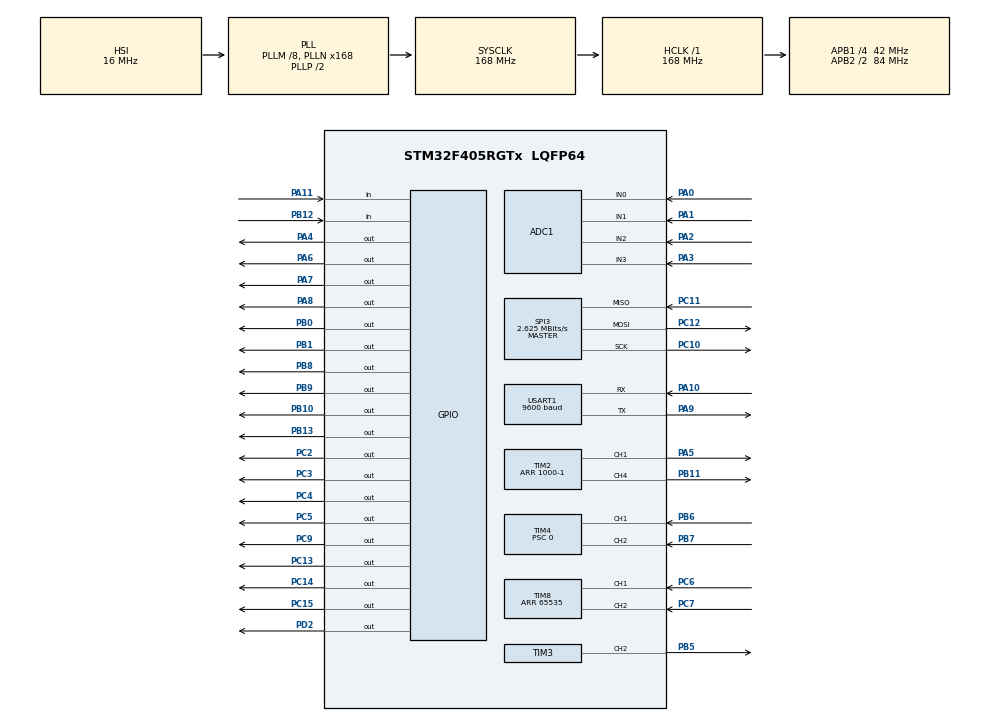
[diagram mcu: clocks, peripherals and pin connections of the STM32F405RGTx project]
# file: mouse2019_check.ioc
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ADC1.Channel-13\#ChannelRegularConversion=ADC_CHANNEL_0
ADC1.ClockPrescaler=ADC_CLOCK_SYNC_PCLK_DIV4
ADC1.ContinuousConvMode=DISABLE
ADC1.DMAContinuousRequests=DISABLE
ADC1.DiscontinuousConvMode=DISABLE
ADC1.NbrOfConversion=1
ADC1.NbrOfConversionFlag=1
ADC1.Rank-13\#ChannelRegularConversion=1
ADC1.SamplingTime-13\#ChannelRegularConversion=ADC_SAMPLETIME_3CYCLES
ADC1.master=1
Mcu.Family=STM32F4
Mcu.Name=STM32F405RGTx
Mcu.Package=LQFP64
NVIC.PriorityGroup=NVIC_PRIORITYGROUP_4
NVIC.TIM3_IRQn=true\:0\:0\:false\:false\:true\:true\:false
NVIC.TIM4_IRQn=true\:0\:0\:false\:false\:true\:true\:false
NVIC.TIM6_DAC_IRQn=true\:0\:0\:false\:false\:true\:true\:true
PA0-WKUP.Signal=ADCx_IN0
PA1.Signal=ADCx_IN1
PA10.Mode=Asynchronous
PA10.Signal=USART1_RX
PA11.GPIO_Mode=GPIO_MODE_INPUT
PA11.GPIO_PuPd=GPIO_NOPULL
PA11.Signal=GPIO_Input
PA2.Signal=ADCx_IN2
PA3.Signal=ADCx_IN3
PA4.GPIO_ModeDefaultOutputPP=GPIO_MODE_OUTPUT_PP
PA4.GPIO_PuPd=GPIO_NOPULL
PA4.GPIO_Speed=GPIO_SPEED_FREQ_LOW
PA4.PinState=GPIO_PIN_RESET
PA4.Signal=GPIO_Output
PA5.Signal=S_TIM2_CH1_ETR
PA6.GPIO_ModeDefaultOutputPP=GPIO_MODE_OUTPUT_PP
PA6.GPIO_PuPd=GPIO_NOPULL
PA6.GPIO_Speed=GPIO_SPEED_FREQ_LOW
PA6.PinState=GPIO_PIN_RESET
PA6.Signal=GPIO_Output
PA7.PinState=GPIO_PIN_RESET
PA7.Signal=GPIO_Output
PA8.PinState=GPIO_PIN_RESET
PA8.Signal=GPIO_Output
PA9.Mode=Asynchronous
PA9.Signal=USART1_TX
PB0.PinState=GPIO_PIN_RESET
PB0.Signal=GPIO_Output
PB1.PinState=GPIO_PIN_RESET
PB1.Signal=GPIO_Output
PB10.PinState=GPIO_PIN_RESET
PB10.Signal=GPIO_Output
PB11.Signal=S_TIM2_CH4
PB12.GPIO_PuPd=GPIO_PULLUP
PB12.Signal=GPIO_Input
PB13.PinState=GPIO_PIN_RESET
PB13.Signal=GPIO_Output
PB5.Signal=S_TIM3_CH2
PB6.Signal=S_TIM4_CH1
PB7.Signal=S_TIM4_CH2
PB8.GPIO_ModeDefaultOutputPP=GPIO_MODE_OUTPUT_PP
PB8.GPIO_PuPd=GPIO_NOPULL
PB8.GPIO_Speed=GPIO_SPEED_FREQ_LOW
PB8.PinState=GPIO_PIN_RESET
PB8.Signal=GPIO_Output
PB9.PinState=GPIO_PIN_RESET
PB9.Signal=GPIO_Output
PC10.Mode=Full_Duplex_Master
PC10.Signal=SPI3_SCK
PC11.Mode=Full_Duplex_Master
PC11.Signal=SPI3_MISO
PC12.Mode=Full_Duplex_Master
PC12.Signal=SPI3_MOSI
PC13-ANTI_TAMP.GPIO_ModeDefaultOutputPP=GPIO_MODE_OUTPUT_PP
PC13-ANTI_TAMP.GPIO_PuPd=GPIO_NOPULL
PC13-ANTI_TAMP.GPIO_Speed=GPIO_SPEED_FREQ_LOW
PC13-ANTI_TAMP.PinState=GPIO_PIN_RESET
PC13-ANTI_TAMP.Signal=GPIO_Output
PC14-OSC32_IN.PinState=GPIO_PIN_RESET
PC14-OSC32_IN.Signal=GPIO_Output
PC15-OSC32_OUT.PinState=GPIO_PIN_RESET
PC15-OSC32_OUT.Signal=GPIO_Output
PC2.GPIO_ModeDefaultOutputPP=GPIO_MODE_OUTPUT_PP
PC2.GPIO_PuPd=GPIO_NOPULL
PC2.GPIO_Speed=GPIO_SPEED_FREQ_LOW
PC2.PinState=GPIO_PIN_RESET
PC2.Signal=GPIO_Output
PC3.GPIO_ModeDefaultOutputPP=GPIO_MODE_OUTPUT_PP
PC3.GPIO_PuPd=GPIO_NOPULL
PC3.GPIO_Speed=GPIO_SPEED_FREQ_LOW
PC3.PinState=GPIO_PIN_RESET
PC3.Signal=GPIO_Output
PC4.PinState=GPIO_PIN_RESET
PC4.Signal=GPIO_Output
PC5.PinState=GPIO_PIN_RESET
PC5.Signal=GPIO_Output
PC6.Signal=S_TIM8_CH1
PC7.Signal=S_TIM8_CH2
PC9.PinState=GPIO_PIN_RESET
PC9.Signal=GPIO_Output
PD2.PinState=GPIO_PIN_RESET
PD2.Signal=GPIO_Output
ProjectManager.HeapSize=0x200
ProjectManager.StackSize=0x400
ProjectManager.TargetToolchain=STM32CubeIDE
RCC.48MHZClocksFreq_Value=84000000
RCC.AHBFreq_Value=168000000
RCC.APB1CLKDivider=RCC_HCLK_DIV4
RCC.APB1Freq_Value=42000000
RCC.APB1TimFreq_Value=84000000
RCC.APB2CLKDivider=RCC_HCLK_DIV2
RCC.APB2Freq_Value=84000000
RCC.APB2TimFreq_Value=168000000
RCC.CortexFreq_Value=168000000
RCC.HCLKFreq_Value=168000000
RCC.HSE_VALUE=25000000
RCC.HSI_VALUE=16000000
RCC.LSE_VALUE=32768
RCC.PLLM=8
RCC.PLLN=168
RCC.SYSCLKFreq_VALUE=168000000
RCC.SYSCLKSource=RCC_SYSCLKSOURCE_PLLCLK
RCC.VCOOutputFreq_Value=336000000
SH.ADCx_IN0.0=ADC1_IN0,IN0
SH.ADCx_IN1.0=ADC1_IN1,IN1
SH.ADCx_IN2.0=ADC1_IN2,IN2
SH.ADCx_IN3.0=ADC1_IN3,IN3
SH.S_TIM2_CH1_ETR.0=TIM2_CH1,PWM Generation1 CH1
SH.S_TIM2_CH4.0=TIM2_CH4,PWM Generation4 CH4
SH.S_TIM3_CH2.0=TIM3_CH2,PWM Generation2 CH2
SH.S_TIM4_CH1.0=TIM4_CH1,Encoder_Interface
SH.S_TIM4_CH2.0=TIM4_CH2,Encoder_Interface
SH.S_TIM8_CH1.0=TIM8_CH1,Encoder_Interface
SH.S_TIM8_CH2.0=TIM8_CH2,Encoder_Interface
SPI3.BaudRatePrescaler=SPI_BAUDRATEPRESCALER_16
SPI3.CalculateBaudRate=2.625 MBits/s
SPI3.Direction=SPI_DIRECTION_2LINES
SPI3.Mode=SPI_MODE_MASTER
SPI3.VirtualType=VM_MASTER
TIM2.Channel-PWM\ Generation1\ CH1=TIM_CHANNEL_1
TIM2.Channel-PWM\ Generation4\ CH4=TIM_CHANNEL_4
TIM2.Period=1000-1
TIM3.Channel-PWM\ Generation2\ CH2=TIM_CHANNEL_2
TIM3.Period=0
TIM3.Prescaler=84-1
TIM4.EncoderMode=TIM_ENCODERMODE_TI12
TIM4.Period=65535
TIM4.Prescaler=0
TIM6.Period=1000-1
TIM6.Prescaler=84-1
TIM8.CounterMode=TIM_COUNTERMODE_UP
TIM8.EncoderMode=TIM_ENCODERMODE_TI12
TIM8.Period=65535
USART1.BaudRate=9600
USART1.VirtualMode=VM_ASYNC
VP_TIM2_VS_ClockSourceINT.Mode=Internal
VP_TIM3_VS_ClockSourceINT.Mode=Internal
VP_TIM6_VS_ClockSourceINT.Mode=Enable_Timer
board=custom

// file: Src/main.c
/* USER CODE BEGIN Header */
/**
  ******************************************************************************
  * @file           : main.c
  * @brief          : Main program body
  ******************************************************************************
  * @attention
  *
  * <h2><center>&copy; Copyright (c) 2019 STMicroelectronics.
  * All rights reserved.</center></h2>
  *
  * This software component is licensed by ST under BSD 3-Clause license,
  * the "License"; You may not use this file except in compliance with the
  * License. You may obtain a copy of the License at:
  *                        opensource.org/licenses/BSD-3-Clause
  *
  ******************************************************************************
  */
/* USER CODE END Header */

#include "main.h"

/* USER CODE BEGIN Includes */
#include <stdio.h>
//#include <string.h>
#include "math.h"

#define MAIN_C_
#include "global.h"

/* USER CODE END Includes */

/* USER CODE BEGIN PD */

#define DIAMETER 24.2//22.5//23.4
#define TREAD 66
#define sensor_wait 3000
#define log_allay 200

//gyro
#define WHO_AM_I 0x75
#define PWR_MGMT_1 0x6B
#define CONFIG 0x1A
#define GYRO_CONFIG 0x1B
#define GYRO_ZOUT_H 0x47
#define GYRO_ZOUT_L 0x48
#define GYRO_FACTOR 16.4

/* USER CODE END PD */

ADC_HandleTypeDef hadc1;

SPI_HandleTypeDef hspi3;

TIM_HandleTypeDef htim2;
TIM_HandleTypeDef htim3;
TIM_HandleTypeDef htim4;
TIM_HandleTypeDef htim6;
TIM_HandleTypeDef htim8;

UART_HandleTypeDef huart1;

/* USER CODE BEGIN PV */

float cnt_r = 0;
float dist_r = 0;
float speed_r = 0;
float cnt_l = 0;
float dist_l = 0;
float speed_l = 0;
float speed_G = 0;

int mode = 0;
int cnt = 0;
int get_cnt = 0;

float speed_min_l = 0;
float speed_max_l = 0;
float speed_min_r = 0;
float speed_max_r = 0;
float pulse_l, pulse_r;

float accel_l = 0;
float accel_r = 0;
float target_speed_l = 0;
float target_speed_r = 0;
float target_dist = 0;

float degree_z = 0;
float target_degree_z = 0;
float target_omega_z = 0;
float target_degaccel_z = 0;
float omega_min = 0;
float omega_max = 0;

int get_speed_l[log_allay];
int get_speed_r[log_allay];

int value1, value2, value3, value4;

float epsilon_sum = 0; 	//dif sum
float old_epsilon = 0; 	//
float epsilon_dif = 0;	//dif of dif
float epsilon_l = 0; 	//dif between target & current
float epsilon_r = 0;	//dif between target & current
float Kp = 4;
float Ti = 1000;
float Td = 0;

//#define NUMBER_OF_VRS 4
//static uint16_t vr_values[NUMBER_OF_VRS];

//#define ADC_CONVERTED_DATA_BUFFER_SIZE ((uint32_t) 4)

/* USER CODE END PV */

void SystemClock_Config(void);
static void MX_GPIO_Init(void);
static void MX_USART1_UART_Init(void);
static void MX_ADC1_Init(void);
static void MX_TIM4_Init(void);
static void MX_TIM8_Init(void);
static void MX_TIM2_Init(void);
static void MX_TIM6_Init(void);
static void MX_TIM3_Init(void);
static void MX_SPI3_Init(void);
/* USER CODE BEGIN PFP */
void buzzer(int, int);
int get_adc_value(ADC_HandleTypeDef*, uint32_t);
void gyro_init(void);
uint8_t read_byte(uint8_t reg);
void write_byte(uint8_t reg, uint8_t val);
float gyro_read_z(void);
void drive_dir(uint8_t, uint8_t);

/* USER CODE END PFP */

/* USER CODE BEGIN 0 */
int __io_putchar(int c){
  if(c == '\n'){
    int _c = '\r';
    HAL_UART_Transmit(&huart1, &_c, 1, 1);
  }
  HAL_UART_Transmit(&huart1, &c, 1, 1);
  return 0;
}

void HAL_TIM_PeriodElapsedCallback(TIM_HandleTypeDef *htim){
	TIM_OC_InitTypeDef ConfigOC;
	ConfigOC.OCMode = TIM_OCMODE_PWM1;
	ConfigOC.OCPolarity = TIM_OCPOLARITY_HIGH;
	ConfigOC.OCFastMode = TIM_OCFAST_DISABLE;

	if(htim == &htim6){
/*	  ledOn ++;
	  ledOn = ledOn % 2;
	  switch(ledOn){
	  case 0:
		  HAL_GPIO_WritePin(GPIOC, GPIO_PIN_2, GPIO_PIN_SET);   //
		  break;

	  case 1:
		  HAL_GPIO_WritePin(GPIOC, GPIO_PIN_2, GPIO_PIN_RESET);   //
		  break;
	  }
*/

		cnt_l = TIM4 -> CNT;
		cnt_r = TIM8 -> CNT;
		if(cnt_l > 40000) cnt_l = cnt_l - 65535;
		if(cnt_r > 40000) cnt_r = cnt_r - 65535;
		cnt_r = cnt_r * -1;

		dist_l = dist_l + cnt_l * (DIAMETER * M_PI * 11 / 40 / 4096 / 4);
		dist_r = dist_r + cnt_r * (DIAMETER * M_PI * 11 / 40 / 4096 / 4);

		speed_l = cnt_l * (DIAMETER * M_PI * 11 / 40 / 4096 / 4) / 0.001;
		speed_r = cnt_r * (DIAMETER * M_PI * 11 / 40 / 4096 / 4) / 0.001;

		TIM4 -> CNT = 0;
		TIM8 -> CNT = 0;

		if(MF.FLAG.DRV){
			target_speed_l += accel_l * 0.001;
			target_speed_l = max(min(target_speed_l, speed_max_l), speed_min_l);
			epsilon_l = target_speed_l - speed_l;
			pulse_l = Kp * epsilon_l;
			if(pulse_l > 0){
				drive_dir(0, 0);
				ConfigOC.Pulse = pulse_l;
				HAL_TIM_PWM_ConfigChannel(&htim2, &ConfigOC, TIM_CHANNEL_1);
				HAL_TIM_PWM_Start(&htim2,TIM_CHANNEL_1);
			}
			else if(pulse_l < 0){
				drive_dir(0, 1);
				ConfigOC.Pulse = -pulse_l;
				HAL_TIM_PWM_ConfigChannel(&htim2, &ConfigOC, TIM_CHANNEL_1);
				HAL_TIM_PWM_Start(&htim2,TIM_CHANNEL_1);
			}

			target_speed_r += accel_r * 0.001;
			target_speed_r = max(min(target_speed_r, speed_max_r), speed_min_r);
			epsilon_r = target_speed_r - speed_r;
			pulse_r = Kp * epsilon_r;
			if(pulse_r > 0){
				drive_dir(1, 0);
				ConfigOC.Pulse = pulse_r;
				HAL_TIM_PWM_ConfigChannel(&htim2, &ConfigOC, TIM_CHANNEL_4);
				HAL_TIM_PWM_Start(&htim2,TIM_CHANNEL_4);
			}
			else if(pulse_r < 0){
				drive_dir(1, 1);
				ConfigOC.Pulse = -pulse_r;
				HAL_TIM_PWM_ConfigChannel(&htim2, &ConfigOC, TIM_CHANNEL_4);
				HAL_TIM_PWM_Start(&htim2,TIM_CHANNEL_4);
			}
			if(cnt >= 5 && MF.FLAG.LOG){
				cnt = 0;
				if(get_cnt < log_allay){
					get_speed_l[get_cnt] = speed_l;
					get_speed_r[get_cnt] = speed_r;
					get_cnt++;
				}
			}
		}else{
			drive_dir(0, 2);
			drive_dir(1, 2);
		}

		//gyro interrupt
		degree_z += gyro_read_z() * 0.001;

		if(MF.FLAG.ENKAI){
			target_dist = TREAD*M_PI/360*(degree_z-target_degree_z);
			if(target_dist > 0){
				target_speed_l = sqrt(2*accel_l*target_dist);
				target_speed_r = -1 * target_speed_l;
			}else{
				target_speed_l = sqrt(2*accel_l*target_dist*-1)*-1;
				target_speed_r = -1 * target_speed_l;
			}

			epsilon_l = target_speed_l - speed_l;
			pulse_l = Kp * epsilon_l;
			if(pulse_l > 0){
				drive_dir(0, 0);
				ConfigOC.Pulse = pulse_l;
				HAL_TIM_PWM_ConfigChannel(&htim2, &ConfigOC, TIM_CHANNEL_1);
				HAL_TIM_PWM_Start(&htim2,TIM_CHANNEL_1);
			}
			else if(pulse_l < 0){
				drive_dir(0, 1);
				ConfigOC.Pulse = -pulse_l;
				HAL_TIM_PWM_ConfigChannel(&htim2, &ConfigOC, TIM_CHANNEL_1);
				HAL_TIM_PWM_Start(&htim2,TIM_CHANNEL_1);
			}

			epsilon_r = target_speed_r - speed_r;
			pulse_r = Kp * epsilon_r;
			if(pulse_r > 0){
				drive_dir(1, 0);
				ConfigOC.Pulse = pulse_r;
				HAL_TIM_PWM_ConfigChannel(&htim2, &ConfigOC, TIM_CHANNEL_4);
				HAL_TIM_PWM_Start(&htim2,TIM_CHANNEL_4);
			}
			else if(pulse_r < 0){
				drive_dir(1, 1);
				ConfigOC.Pulse = -pulse_r;
				HAL_TIM_PWM_ConfigChannel(&htim2, &ConfigOC, TIM_CHANNEL_4);
				HAL_TIM_PWM_Start(&htim2,TIM_CHANNEL_4);
			}
		}

		if(MF.FLAG.GYRO){
			target_omega_z += target_degaccel_z * 0.001;
			target_omega_z = max(min(target_omega_z, omega_max), omega_min);
			target_speed_l = speed_G + target_omega_z/180*M_PI*TREAD/2;
			target_speed_r = speed_G - target_omega_z/180*M_PI*TREAD/2;

			epsilon_l = target_speed_l - speed_l;
			pulse_l = Kp * epsilon_l;
			if(pulse_l > 0){
				drive_dir(0, 0);
				ConfigOC.Pulse = pulse_l;
				HAL_TIM_PWM_ConfigChannel(&htim2, &ConfigOC, TIM_CHANNEL_1);
				HAL_TIM_PWM_Start(&htim2,TIM_CHANNEL_1);
			}
			else if(pulse_l < 0){
				drive_dir(0, 1);
				ConfigOC.Pulse = -pulse_l;
				HAL_TIM_PWM_ConfigChannel(&htim2, &ConfigOC, TIM_CHANNEL_1);
				HAL_TIM_PWM_Start(&htim2,TIM_CHANNEL_1);
			}

			epsilon_r = target_speed_r - speed_r;
			pulse_r = Kp * epsilon_r;
			if(pulse_r > 0){
				drive_dir(1, 0);
				ConfigOC.Pulse = pulse_r;
				HAL_TIM_PWM_ConfigChannel(&htim2, &ConfigOC, TIM_CHANNEL_4);
				HAL_TIM_PWM_Start(&htim2,TIM_CHANNEL_4);
			}
			else if(pulse_r < 0){
				drive_dir(1, 1);
				ConfigOC.Pulse = -pulse_r;
				HAL_TIM_PWM_ConfigChannel(&htim2, &ConfigOC, TIM_CHANNEL_4);
				HAL_TIM_PWM_Start(&htim2,TIM_CHANNEL_4);
			}
		}

		//ADchange interrupt
		uint16_t delay = 0;
		cnt++;
		mode = (mode+1)%2;

		switch(mode){
		  case 0:
				HAL_GPIO_WritePin(GPIOC, GPIO_PIN_14, GPIO_PIN_SET); 	//L
				for(delay=0; delay<sensor_wait; delay++);
				value4 = get_adc_value(&hadc1, ADC_CHANNEL_3);			//L
				HAL_GPIO_WritePin(GPIOC, GPIO_PIN_14, GPIO_PIN_RESET);

				HAL_GPIO_WritePin(GPIOA, GPIO_PIN_8, GPIO_PIN_SET);   	//R
				for(delay=0; delay<sensor_wait; delay++);
				value2 = get_adc_value(&hadc1, ADC_CHANNEL_1);			//R
				HAL_GPIO_WritePin(GPIOA, GPIO_PIN_8, GPIO_PIN_RESET);
			break;

		  case 1:
				HAL_GPIO_WritePin(GPIOC, GPIO_PIN_15, GPIO_PIN_SET);  	//FL
				for(delay=0; delay<sensor_wait; delay++);
				value3 = get_adc_value(&hadc1, ADC_CHANNEL_2);			//FL
				HAL_GPIO_WritePin(GPIOC, GPIO_PIN_15, GPIO_PIN_RESET);

				HAL_GPIO_WritePin(GPIOC, GPIO_PIN_9, GPIO_PIN_SET);   	//FR
				for(delay=0; delay<sensor_wait; delay++);
				value1 = get_adc_value(&hadc1, ADC_CHANNEL_0);			//FR
				HAL_GPIO_WritePin(GPIOC, GPIO_PIN_9, GPIO_PIN_RESET);
			break;
		}
	}
}

/* USER CODE END 0 */

int main(void)
{

  /* MCU Configuration--------------------------------------------------------*/

  /* Reset of all peripherals, Initializes the Flash interface and the Systick. */
  HAL_Init();

  /* Configure the system clock */
  SystemClock_Config();

  /* Initialize all configured peripherals */
  MX_GPIO_Init();
  MX_USART1_UART_Init();
  MX_ADC1_Init();
  MX_TIM4_Init();
  MX_TIM8_Init();
  MX_TIM2_Init();
  MX_TIM6_Init();
  MX_TIM3_Init();
  MX_SPI3_Init();
  /* USER CODE BEGIN 2 */
  gyro_init();

  printf("Welcome to WMMC !\n");

  int val = 0;

  setbuf(stdout, NULL);

  HAL_TIM_Encoder_Start(&htim4,TIM_CHANNEL_ALL);
  HAL_TIM_Encoder_Start(&htim8,TIM_CHANNEL_ALL);

  int pulse = 0;

  TIM_OC_InitTypeDef ConfigOC;
  ConfigOC.OCMode = TIM_OCMODE_PWM1;
  ConfigOC.OCPolarity = TIM_OCPOLARITY_HIGH;
  ConfigOC.OCFastMode = TIM_OCFAST_DISABLE;

  HAL_TIM_Base_Start_IT(&htim6);

  /* USER CODE END 2 */

  /* Infinite loop */
  /* USER CODE BEGIN WHILE */
  while (1)
  {
	int cnt_r2, cnt_l2, dist_r2, dist_l2, speed_r2, speed_l2;
	cnt_r2 = cnt_r * 10;
	cnt_l2 = cnt_l * 10;
	dist_r2 = dist_r * 10;
	dist_l2 = dist_l * 10;
	speed_r2 = speed_r * 10;
	speed_l2 = speed_l * 10;

/*LED check
    HAL_GPIO_WritePin(GPIOA, GPIO_PIN_4, GPIO_PIN_SET);
    HAL_GPIO_WritePin(GPIOA, GPIO_PIN_6, GPIO_PIN_SET);
    HAL_GPIO_WritePin(GPIOA, GPIO_PIN_7, GPIO_PIN_SET);
    HAL_GPIO_WritePin(GPIOB, GPIO_PIN_13, GPIO_PIN_SET);
    HAL_GPIO_WritePin(GPIOC, GPIO_PIN_2, GPIO_PIN_SET);
    HAL_GPIO_WritePin(GPIOC, GPIO_PIN_3, GPIO_PIN_SET);

    HAL_Delay(1000);

    HAL_GPIO_WritePin(GPIOA, GPIO_PIN_4, GPIO_PIN_RESET);
    HAL_GPIO_WritePin(GPIOA, GPIO_PIN_6, GPIO_PIN_RESET);
    HAL_GPIO_WritePin(GPIOA, GPIO_PIN_7, GPIO_PIN_RESET);
    HAL_GPIO_WritePin(GPIOB, GPIO_PIN_13, GPIO_PIN_RESET);
    HAL_GPIO_WritePin(GPIOC, GPIO_PIN_2, GPIO_PIN_RESET);
    HAL_GPIO_WritePin(GPIOC, GPIO_PIN_3, GPIO_PIN_RESET);

    HAL_Delay(1000);
*/

/*full color LED check
    HAL_GPIO_WritePin(GPIOB, GPIO_PIN_8, GPIO_PIN_SET);
    HAL_GPIO_WritePin(GPIOB, GPIO_PIN_9, GPIO_PIN_SET);
    HAL_GPIO_WritePin(GPIOC, GPIO_PIN_13, GPIO_PIN_RESET);

    HAL_Delay(1000);

    HAL_GPIO_WritePin(GPIOB, GPIO_PIN_8, GPIO_PIN_RESET);
    HAL_GPIO_WritePin(GPIOB, GPIO_PIN_9, GPIO_PIN_SET);
    HAL_GPIO_WritePin(GPIOC, GPIO_PIN_13, GPIO_PIN_SET);

    HAL_Delay(1000);

    HAL_GPIO_WritePin(GPIOB, GPIO_PIN_8, GPIO_PIN_SET);
    HAL_GPIO_WritePin(GPIOB, GPIO_PIN_9, GPIO_PIN_RESET);
    HAL_GPIO_WritePin(GPIOC, GPIO_PIN_13, GPIO_PIN_SET);

    HAL_Delay(1000);

    HAL_GPIO_WritePin(GPIOB, GPIO_PIN_8, GPIO_PIN_RESET);
    HAL_GPIO_WritePin(GPIOB, GPIO_PIN_9, GPIO_PIN_RESET);
    HAL_GPIO_WritePin(GPIOC, GPIO_PIN_13, GPIO_PIN_SET);

    HAL_Delay(1000);

    HAL_GPIO_WritePin(GPIOB, GPIO_PIN_8, GPIO_PIN_RESET);
    HAL_GPIO_WritePin(GPIOB, GPIO_PIN_9, GPIO_PIN_SET);
    HAL_GPIO_WritePin(GPIOC, GPIO_PIN_13, GPIO_PIN_RESET);

    HAL_Delay(1000);

    HAL_GPIO_WritePin(GPIOB, GPIO_PIN_8, GPIO_PIN_SET);
    HAL_GPIO_WritePin(GPIOB, GPIO_PIN_9, GPIO_PIN_RESET);
    HAL_GPIO_WritePin(GPIOC, GPIO_PIN_13, GPIO_PIN_RESET);

    HAL_Delay(1000);

    HAL_GPIO_WritePin(GPIOB, GPIO_PIN_8, GPIO_PIN_RESET);
    HAL_GPIO_WritePin(GPIOB, GPIO_PIN_9, GPIO_PIN_RESET);
    HAL_GPIO_WritePin(GPIOC, GPIO_PIN_13, GPIO_PIN_RESET);

    HAL_Delay(1000);
*/

/*push switch check
    if( HAL_GPIO_ReadPin(GPIOA, GPIO_PIN_11) == GPIO_PIN_RESET ) {
       HAL_GPIO_WritePin(GPIOA, GPIO_PIN_4, GPIO_PIN_SET);
    } else {
       HAL_GPIO_WritePin(GPIOA, GPIO_PIN_4, GPIO_PIN_RESET);
    }
*/

/*mode select
    if(mode & 0b001){
      HAL_GPIO_WritePin(GPIOA, GPIO_PIN_4, GPIO_PIN_SET);
    }else{
      HAL_GPIO_WritePin(GPIOA, GPIO_PIN_4, GPIO_PIN_RESET);
    }
    if(mode & 0b010){
      HAL_GPIO_WritePin(GPIOA, GPIO_PIN_6, GPIO_PIN_SET);
    }else{
      HAL_GPIO_WritePin(GPIOA, GPIO_PIN_6, GPIO_PIN_RESET);
    }
    if(mode & 0b100){
      HAL_GPIO_WritePin(GPIOA, GPIO_PIN_7, GPIO_PIN_SET);
    }else{
      HAL_GPIO_WritePin(GPIOA, GPIO_PIN_7, GPIO_PIN_RESET);
    }

    if(HAL_GPIO_ReadPin(GPIOA, GPIO_PIN_11) == GPIO_PIN_RESET){
      HAL_Delay(100);
      while(HAL_GPIO_ReadPin(GPIOA, GPIO_PIN_11) == GPIO_PIN_RESET);
      mode++;
      if(mode > 7){
        mode = 0;
      }
      printf("Mode : %d\n", mode);
    }

    if(HAL_GPIO_ReadPin(GPIOA, GPIO_PIN_11) == GPIO_PIN_RESET){
      HAL_Delay(1000);
      while(HAL_GPIO_ReadPin(GPIOA, GPIO_PIN_11) == GPIO_PIN_RESET);
      switch(mode){
        case 0:
          HAL_GPIO_WritePin(GPIOB, GPIO_PIN_8, GPIO_PIN_SET);
          HAL_GPIO_WritePin(GPIOB, GPIO_PIN_9, GPIO_PIN_SET);
          HAL_GPIO_WritePin(GPIOC, GPIO_PIN_13, GPIO_PIN_RESET);
          break;

        case 1:
          HAL_GPIO_WritePin(GPIOB, GPIO_PIN_8, GPIO_PIN_RESET);
          HAL_GPIO_WritePin(GPIOB, GPIO_PIN_9, GPIO_PIN_SET);
          HAL_GPIO_WritePin(GPIOC, GPIO_PIN_13, GPIO_PIN_SET);
          break;

        case 2:
          HAL_GPIO_WritePin(GPIOB, GPIO_PIN_8, GPIO_PIN_SET);
          HAL_GPIO_WritePin(GPIOB, GPIO_PIN_9, GPIO_PIN_RESET);
          HAL_GPIO_WritePin(GPIOC, GPIO_PIN_13, GPIO_PIN_SET);
          break;

        case 3:
          HAL_GPIO_WritePin(GPIOB, GPIO_PIN_8, GPIO_PIN_RESET);
          HAL_GPIO_WritePin(GPIOB, GPIO_PIN_9, GPIO_PIN_RESET);
          HAL_GPIO_WritePin(GPIOC, GPIO_PIN_13, GPIO_PIN_SET);
          break;

        case 4:
          HAL_GPIO_WritePin(GPIOB, GPIO_PIN_8, GPIO_PIN_RESET);
          HAL_GPIO_WritePin(GPIOB, GPIO_PIN_9, GPIO_PIN_SET);
          HAL_GPIO_WritePin(GPIOC, GPIO_PIN_13, GPIO_PIN_RESET);
          break;

        case 5:
          HAL_GPIO_WritePin(GPIOB, GPIO_PIN_8, GPIO_PIN_SET);
          HAL_GPIO_WritePin(GPIOB, GPIO_PIN_9, GPIO_PIN_RESET);
          HAL_GPIO_WritePin(GPIOC, GPIO_PIN_13, GPIO_PIN_RESET);
          break;

        case 6:
          HAL_GPIO_WritePin(GPIOB, GPIO_PIN_8, GPIO_PIN_RESET);
          HAL_GPIO_WritePin(GPIOB, GPIO_PIN_9, GPIO_PIN_RESET);
          HAL_GPIO_WritePin(GPIOC, GPIO_PIN_13, GPIO_PIN_RESET);
          break;

        case 7:
          HAL_GPIO_WritePin(GPIOB, GPIO_PIN_8, GPIO_PIN_SET);
          HAL_GPIO_WritePin(GPIOB, GPIO_PIN_9, GPIO_PIN_SET);
          HAL_GPIO_WritePin(GPIOC, GPIO_PIN_13, GPIO_PIN_SET);
          break;

      }
    }
*/

/*sensor ON&OFF
    HAL_GPIO_WritePin(GPIOC, GPIO_PIN_9, GPIO_PIN_SET);
    HAL_GPIO_WritePin(GPIOA, GPIO_PIN_8, GPIO_PIN_SET);
    HAL_GPIO_WritePin(GPIOC, GPIO_PIN_14, GPIO_PIN_SET);
    HAL_GPIO_WritePin(GPIOC, GPIO_PIN_15, GPIO_PIN_SET);

    HAL_Delay(1000);

    HAL_GPIO_WritePin(GPIOC, GPIO_PIN_9, GPIO_PIN_RESET);
    HAL_GPIO_WritePin(GPIOA, GPIO_PIN_8, GPIO_PIN_RESET);
    HAL_GPIO_WritePin(GPIOC, GPIO_PIN_14, GPIO_PIN_RESET);
    HAL_GPIO_WritePin(GPIOC, GPIO_PIN_15, GPIO_PIN_RESET);

    HAL_Delay(1000);
*/

/*AD change check
	HAL_ADC_Start(&hadc1);
	HAL_ADC_PollForConversion(&hadc1, 100); //ADC
	val = HAL_ADC_GetValue(&hadc1);

	printf("%d\n",val);
	HAL_Delay(10);
	mode++;
	mode = mode%2;

	switch(mode){
	  case 0:
		HAL_GPIO_WritePin(GPIOC, GPIO_PIN_9, GPIO_PIN_SET);   //FR
		HAL_GPIO_WritePin(GPIOA, GPIO_PIN_8, GPIO_PIN_SET);   //R
		HAL_GPIO_WritePin(GPIOC, GPIO_PIN_14, GPIO_PIN_SET);  //L
		HAL_GPIO_WritePin(GPIOC, GPIO_PIN_15, GPIO_PIN_SET);  //FL
		break;

	  case 1:
		HAL_GPIO_WritePin(GPIOC, GPIO_PIN_9, GPIO_PIN_RESET);
		HAL_GPIO_WritePin(GPIOA, GPIO_PIN_8, GPIO_PIN_RESET);
		HAL_GPIO_WritePin(GPIOC, GPIO_PIN_14, GPIO_PIN_RESET);
		HAL_GPIO_WritePin(GPIOC, GPIO_PIN_15, GPIO_PIN_RESET);
		break;
	}
*/

/*AD change check
	HAL_Delay(1);

	mode++;
	cnt++;
	mode = mode%2;

	switch(mode){
	  case 0:
		HAL_GPIO_WritePin(GPIOC, GPIO_PIN_9, GPIO_PIN_SET);   //FR
		HAL_GPIO_WritePin(GPIOA, GPIO_PIN_8, GPIO_PIN_SET);   //R
		HAL_GPIO_WritePin(GPIOC, GPIO_PIN_14, GPIO_PIN_SET);  //L
		HAL_GPIO_WritePin(GPIOC, GPIO_PIN_15, GPIO_PIN_SET);  //FL
		break;

	  case 1:
		HAL_GPIO_WritePin(GPIOC, GPIO_PIN_9, GPIO_PIN_RESET);
		HAL_GPIO_WritePin(GPIOA, GPIO_PIN_8, GPIO_PIN_RESET);
		HAL_GPIO_WritePin(GPIOC, GPIO_PIN_14, GPIO_PIN_RESET);
		HAL_GPIO_WritePin(GPIOC, GPIO_PIN_15, GPIO_PIN_RESET);
		break;
	}

	value1 = get_adc_value(&hadc1, ADC_CHANNEL_0);	//FR
	value2 = get_adc_value(&hadc1, ADC_CHANNEL_1);	//R
	value3 = get_adc_value(&hadc1, ADC_CHANNEL_2);	//FL
	value4 = get_adc_value(&hadc1, ADC_CHANNEL_3);	//L
	if(cnt >= 101){
		printf("FR:%3d, R:%3d, FL:%3d, L:%3d\n", value1, value2, value3, value4);
		cnt = 0;
	}
*/

/*AD change interrupt check
if(cnt >= 101){
	printf("FR:%3d, R:%3d, FL:%3d, L:%3d\n", value1, value2, value3, value4);
	cnt = 0;
}
*/

/*AD change x4??
    HAL_GPIO_WritePin(GPIOC, GPIO_PIN_9, GPIO_PIN_SET);   //FR
    HAL_GPIO_WritePin(GPIOA, GPIO_PIN_8, GPIO_PIN_SET);   //R
    HAL_GPIO_WritePin(GPIOC, GPIO_PIN_14, GPIO_PIN_SET);  //L
    HAL_GPIO_WritePin(GPIOC, GPIO_PIN_15, GPIO_PIN_SET);  //FL

    HAL_ADC_Start(&hadc1);
    HAL_ADC_PollForConversion(&hadc1, 100); //ADC

    value1 = HAL_ADC_GetValue(&hadc1);

    HAL_ADC_Start(&hadc1);
    HAL_ADC_PollForConversion(&hadc1, 100); //ADC

    value2 = HAL_ADC_GetValue(&hadc1);

    HAL_ADC_Start(&hadc1);
    HAL_ADC_PollForConversion(&hadc1, 100); //ADC

    value3 = HAL_ADC_GetValue(&hadc1);

    HAL_ADC_Start(&hadc1);
    HAL_ADC_PollForConversion(&hadc1, 100); //ADC

    value4 = HAL_ADC_GetValue(&hadc1);

    HAL_ADC_Stop(&hadc1);

    printf("FR:%4d,  R:%4d,  FL:%4d,  L:%4d \n", value1, value2, value3, value4);

    HAL_Delay(100);
*/

/*AD change DMA
	printf("FR: %u, R: %u, FL: %u, L: %u\n\n", g_ADCBuffer[0], g_ADCBuffer[1], g_ADCBuffer[2], g_ADCBuffer[3]); //FR
	//printf("R: %d\n", g_ADCBuffer[1]); //R
	//printf("FL: %d\n", g_ADCBuffer[2]); //FL
	//printf("L: %d\n", g_ADCBuffer[3]); //L

    mode++;
    mode = mode%2;

    switch(mode){
      case 0:
        HAL_GPIO_WritePin(GPIOC, GPIO_PIN_9, GPIO_PIN_SET);   //FR
        HAL_GPIO_WritePin(GPIOA, GPIO_PIN_8, GPIO_PIN_SET);   //R
        HAL_GPIO_WritePin(GPIOC, GPIO_PIN_14, GPIO_PIN_SET);  //L
        HAL_GPIO_WritePin(GPIOC, GPIO_PIN_15, GPIO_PIN_SET);  //FL
        printf("ON \n");
        break;

      case 1:
        HAL_GPIO_WritePin(GPIOC, GPIO_PIN_9, GPIO_PIN_RESET);
        HAL_GPIO_WritePin(GPIOA, GPIO_PIN_8, GPIO_PIN_RESET);
        HAL_GPIO_WritePin(GPIOC, GPIO_PIN_14, GPIO_PIN_RESET);
        HAL_GPIO_WritePin(GPIOC, GPIO_PIN_15, GPIO_PIN_RESET);
        printf("OFF \n");
        break;
    }

	HAL_Delay(500);
*/

/*Timer LED ON&OFF
 * Written in Interrupt
 */

/*encoder R check
	cnt = TIM8 -> CNT;

	printf("%d\n", cnt);

	HAL_Delay(100);
*/

/*encoder L check
    cnt = TIM4 -> CNT;

    printf("%d\n", cnt);

    HAL_Delay(100);
*/

/*encoder R mode select
    cnt = TIM8 -> CNT;

    printf("%d\n", cnt);

    HAL_Delay(100);

    if(mode & 0b001){
      HAL_GPIO_WritePin(GPIOA, GPIO_PIN_4, GPIO_PIN_SET);
    }else{
      HAL_GPIO_WritePin(GPIOA, GPIO_PIN_4, GPIO_PIN_RESET);
    }
    if(mode & 0b010){
      HAL_GPIO_WritePin(GPIOA, GPIO_PIN_6, GPIO_PIN_SET);
    }else{
      HAL_GPIO_WritePin(GPIOA, GPIO_PIN_6, GPIO_PIN_RESET);
    }
    if(mode & 0b100){
      HAL_GPIO_WritePin(GPIOA, GPIO_PIN_7, GPIO_PIN_SET);
    }else{
      HAL_GPIO_WritePin(GPIOA, GPIO_PIN_7, GPIO_PIN_RESET);
    }

    val = cnt - cnt_old;

    if(val >= 40000){
      mode++;
      if(mode > 7){
        mode = 0;
      }
      printf("Mode : %d\n", mode);
    }
    if(val <= -40000){
      mode--;
      if(mode < 0){
        mode = 7;
      }
      printf("Mode : %d\n", mode);
    }

    if(HAL_GPIO_ReadPin(GPIOA, GPIO_PIN_11) == GPIO_PIN_RESET){
      HAL_Delay(1000);
      while(HAL_GPIO_ReadPin(GPIOA, GPIO_PIN_11) == GPIO_PIN_RESET);
      switch(mode){
        case 0:
          HAL_GPIO_WritePin(GPIOB, GPIO_PIN_8, GPIO_PIN_SET);
          HAL_GPIO_WritePin(GPIOB, GPIO_PIN_9, GPIO_PIN_SET);
          HAL_GPIO_WritePin(GPIOC, GPIO_PIN_13, GPIO_PIN_RESET);
          break;

        case 1:
          HAL_GPIO_WritePin(GPIOB, GPIO_PIN_8, GPIO_PIN_RESET);
          HAL_GPIO_WritePin(GPIOB, GPIO_PIN_9, GPIO_PIN_SET);
          HAL_GPIO_WritePin(GPIOC, GPIO_PIN_13, GPIO_PIN_SET);
          break;

        case 2:
          HAL_GPIO_WritePin(GPIOB, GPIO_PIN_8, GPIO_PIN_SET);
          HAL_GPIO_WritePin(GPIOB, GPIO_PIN_9, GPIO_PIN_RESET);
          HAL_GPIO_WritePin(GPIOC, GPIO_PIN_13, GPIO_PIN_SET);
          break;

        case 3:
          HAL_GPIO_WritePin(GPIOB, GPIO_PIN_8, GPIO_PIN_RESET);
          HAL_GPIO_WritePin(GPIOB, GPIO_PIN_9, GPIO_PIN_RESET);
          HAL_GPIO_WritePin(GPIOC, GPIO_PIN_13, GPIO_PIN_SET);
          break;

        case 4:
          HAL_GPIO_WritePin(GPIOB, GPIO_PIN_8, GPIO_PIN_RESET);
          HAL_GPIO_WritePin(GPIOB, GPIO_PIN_9, GPIO_PIN_SET);
          HAL_GPIO_WritePin(GPIOC, GPIO_PIN_13, GPIO_PIN_RESET);
          break;

        case 5:
          HAL_GPIO_WritePin(GPIOB, GPIO_PIN_8, GPIO_PIN_SET);
          HAL_GPIO_WritePin(GPIOB, GPIO_PIN_9, GPIO_PIN_RESET);
          HAL_GPIO_WritePin(GPIOC, GPIO_PIN_13, GPIO_PIN_RESET);
          break;

        case 6:
          HAL_GPIO_WritePin(GPIOB, GPIO_PIN_8, GPIO_PIN_RESET);
          HAL_GPIO_WritePin(GPIOB, GPIO_PIN_9, GPIO_PIN_RESET);
          HAL_GPIO_WritePin(GPIOC, GPIO_PIN_13, GPIO_PIN_RESET);
          break;

        case 7:
          HAL_GPIO_WritePin(GPIOB, GPIO_PIN_8, GPIO_PIN_SET);
          HAL_GPIO_WritePin(GPIOB, GPIO_PIN_9, GPIO_PIN_SET);
          HAL_GPIO_WritePin(GPIOC, GPIO_PIN_13, GPIO_PIN_SET);
          break;

      }
    }

    cnt_old = cnt;

    //HAL_TIM_Encorder_Stop(&htim4, TIM_CHANNEL_ALL);
*/

/*Timer Encoder Count
	printf("L  cnt:%3d, dist: %3d, speed:%3d\n", cnt_l2, dist_l2, speed_l2);
	printf("R  cnt:%3d, dist: %3d, speed:%3d\n", cnt_r2, dist_r2, speed_r2);

	HAL_Delay(333);
*/

/*PWM check
    pulse = pulse + 3000;

    ConfigOC.Pulse = pulse;
    HAL_TIM_PWM_ConfigChannel(&htim2, &ConfigOC, TIM_CHANNEL_4);
    HAL_TIM_PWM_Start(&htim3, TIM_CHANNEL_4);

    ConfigOC.Pulse = pulse;
    HAL_TIM_PWM_ConfigChannel(&htim2, &ConfigOC, TIM_CHANNEL_2);
    HAL_TIM_PWM_Start(&htim3, TIM_CHANNEL_2);

    if(pulse >= 60000)
    {
      pulse = 0;
    }

    HAL_Delay(100);
*/

/*Motor R rotate forward & back

    HAL_GPIO_WritePin(GPIOB, GPIO_PIN_0, GPIO_PIN_SET);		//STBY

    HAL_GPIO_WritePin(GPIOB, GPIO_PIN_1, GPIO_PIN_SET);		//R_CW
    HAL_GPIO_WritePin(GPIOB, GPIO_PIN_10, GPIO_PIN_RESET);	//R_CCW

    ConfigOC.Pulse = 100;
	HAL_TIM_PWM_ConfigChannel(&htim2, &ConfigOC, TIM_CHANNEL_4);
	HAL_TIM_PWM_Start(&htim2, TIM_CHANNEL_4);

    printf("PWM 10% \n");

    HAL_Delay(500);

    ConfigOC.Pulse = 0;
    HAL_TIM_PWM_ConfigChannel(&htim2, &ConfigOC, TIM_CHANNEL_4);
    HAL_TIM_PWM_Start(&htim2, TIM_CHANNEL_4);

    printf("PWM 0% \n");

    HAL_Delay(500);

    HAL_GPIO_WritePin(GPIOB, GPIO_PIN_1, GPIO_PIN_RESET);		//R_CW
    HAL_GPIO_WritePin(GPIOB, GPIO_PIN_10, GPIO_PIN_SET);	//R_CCW

    ConfigOC.Pulse = 100;
	HAL_TIM_PWM_ConfigChannel(&htim2, &ConfigOC, TIM_CHANNEL_4);
	HAL_TIM_PWM_Start(&htim2, TIM_CHANNEL_4);

    printf("PWM -10% \n");

    HAL_Delay(500);

    ConfigOC.Pulse = 0;
    HAL_TIM_PWM_ConfigChannel(&htim2, &ConfigOC, TIM_CHANNEL_4);
    HAL_TIM_PWM_Start(&htim2, TIM_CHANNEL_4);

    printf("PWM 0% \n");

    HAL_Delay(500);
*/

/*Motor L rotate forward & back

	HAL_GPIO_WritePin(GPIOB, GPIO_PIN_0, GPIO_PIN_SET);		//STBY

	HAL_GPIO_WritePin(GPIOC, GPIO_PIN_5, GPIO_PIN_SET);		//L_CW
	HAL_GPIO_WritePin(GPIOC, GPIO_PIN_4, GPIO_PIN_RESET);	//L_CCW

	ConfigOC.Pulse = 100;
	HAL_TIM_PWM_ConfigChannel(&htim2, &ConfigOC, TIM_CHANNEL_1);
	HAL_TIM_PWM_Start(&htim2, TIM_CHANNEL_1);

	printf("PWM 10% \n");

	HAL_Delay(500);

	ConfigOC.Pulse = 0;
	HAL_TIM_PWM_ConfigChannel(&htim2, &ConfigOC, TIM_CHANNEL_1);
	HAL_TIM_PWM_Start(&htim2, TIM_CHANNEL_1);

	printf("PWM 0% \n");

	HAL_Delay(500);

	HAL_GPIO_WritePin(GPIOC, GPIO_PIN_5, GPIO_PIN_RESET);	//R_CW
	HAL_GPIO_WritePin(GPIOC, GPIO_PIN_4, GPIO_PIN_SET);		//R_CCW

	ConfigOC.Pulse = 100;
	HAL_TIM_PWM_ConfigChannel(&htim2, &ConfigOC, TIM_CHANNEL_1);
	HAL_TIM_PWM_Start(&htim2, TIM_CHANNEL_1);

	printf("PWM -10% \n");

	HAL_Delay(500);

	ConfigOC.Pulse = 0;
	HAL_TIM_PWM_ConfigChannel(&htim2, &ConfigOC, TIM_CHANNEL_1);
	HAL_TIM_PWM_Start(&htim2, TIM_CHANNEL_1);

	printf("PWM 0% \n");

	HAL_Delay(500);
*/

/*Motor R&L rotate forward & back

	HAL_GPIO_WritePin(GPIOB, GPIO_PIN_0, GPIO_PIN_SET);		//STBY

	HAL_GPIO_WritePin(GPIOB, GPIO_PIN_1, GPIO_PIN_SET);		//R_CW
	HAL_GPIO_WritePin(GPIOB, GPIO_PIN_10, GPIO_PIN_RESET);	//R_CCW
	HAL_GPIO_WritePin(GPIOC, GPIO_PIN_5, GPIO_PIN_SET);		//L_CW
	HAL_GPIO_WritePin(GPIOC, GPIO_PIN_4, GPIO_PIN_RESET);	//L_CCW

	ConfigOC.Pulse = 100;
	HAL_TIM_PWM_ConfigChannel(&htim2, &ConfigOC, TIM_CHANNEL_4);
	HAL_TIM_PWM_Start(&htim2, TIM_CHANNEL_4);

	HAL_TIM_PWM_ConfigChannel(&htim2, &ConfigOC, TIM_CHANNEL_1);
	HAL_TIM_PWM_Start(&htim2, TIM_CHANNEL_1);

	printf("PWM 10% \n");

	HAL_Delay(500);

	ConfigOC.Pulse = 0;
	HAL_TIM_PWM_ConfigChannel(&htim2, &ConfigOC, TIM_CHANNEL_4);
	HAL_TIM_PWM_Start(&htim2, TIM_CHANNEL_4);

	HAL_TIM_PWM_ConfigChannel(&htim2, &ConfigOC, TIM_CHANNEL_1);
	HAL_TIM_PWM_Start(&htim2, TIM_CHANNEL_1);

	printf("PWM 0% \n");

	HAL_Delay(500);

	HAL_GPIO_WritePin(GPIOB, GPIO_PIN_1, GPIO_PIN_RESET);	//R_CW
	HAL_GPIO_WritePin(GPIOB, GPIO_PIN_10, GPIO_PIN_SET);	//R_CCW
	HAL_GPIO_WritePin(GPIOC, GPIO_PIN_5, GPIO_PIN_RESET);	//L_CW
	HAL_GPIO_WritePin(GPIOC, GPIO_PIN_4, GPIO_PIN_SET);		//L_CCW

	ConfigOC.Pulse = 100;
	HAL_TIM_PWM_ConfigChannel(&htim2, &ConfigOC, TIM_CHANNEL_4);
	HAL_TIM_PWM_Start(&htim2, TIM_CHANNEL_4);

	HAL_TIM_PWM_ConfigChannel(&htim2, &ConfigOC, TIM_CHANNEL_1);
	HAL_TIM_PWM_Start(&htim2, TIM_CHANNEL_1);

	printf("PWM -10% \n");

	HAL_Delay(500);

	ConfigOC.Pulse = 0;
	HAL_TIM_PWM_ConfigChannel(&htim2, &ConfigOC, TIM_CHANNEL_4);
	HAL_TIM_PWM_Start(&htim2, TIM_CHANNEL_4);

	HAL_TIM_PWM_ConfigChannel(&htim2, &ConfigOC, TIM_CHANNEL_1);
	HAL_TIM_PWM_Start(&htim2, TIM_CHANNEL_1);

	printf("PWM 0% \n");

	HAL_Delay(500);
*/

/*Motor R rotate PWM
    HAL_GPIO_WritePin(GPIOB, GPIO_PIN_0, GPIO_PIN_SET);		//STBY
    HAL_GPIO_WritePin(GPIOB, GPIO_PIN_1, GPIO_PIN_SET);		//R_CW
    HAL_GPIO_WritePin(GPIOB, GPIO_PIN_10, GPIO_PIN_RESET);	//R_CCW

    pulse = pulse + 100;

    ConfigOC.Pulse = pulse;
    HAL_TIM_PWM_ConfigChannel(&htim2, &ConfigOC, TIM_CHANNEL_4);
    HAL_TIM_PWM_Start(&htim2, TIM_CHANNEL_4);

    printf("PWM %4d \n", pulse);

    HAL_Delay(500);

    if(pulse >= 500)
    {
      pulse = 0;
    }
*/

/*Motor L rotate PWM
	HAL_GPIO_WritePin(GPIOB, GPIO_PIN_0, GPIO_PIN_SET);		//STBY
	HAL_GPIO_WritePin(GPIOC, GPIO_PIN_5, GPIO_PIN_SET);		//L_CW
	HAL_GPIO_WritePin(GPIOC, GPIO_PIN_4, GPIO_PIN_RESET);	//L_CCW

	pulse = pulse + 100;

	ConfigOC.Pulse = pulse;
	HAL_TIM_PWM_ConfigChannel(&htim2, &ConfigOC, TIM_CHANNEL_1);
	HAL_TIM_PWM_Start(&htim2, TIM_CHANNEL_1);

	printf("PWM %4d \n", pulse);

	HAL_Delay(500);

	if(pulse >= 500)
	{
		pulse = 0;
	}
*/

/*Motor R&L rotate PWM
	HAL_GPIO_WritePin(GPIOB, GPIO_PIN_0, GPIO_PIN_SET);		//STBY
	HAL_GPIO_WritePin(GPIOB, GPIO_PIN_1, GPIO_PIN_SET);		//R_CW
	HAL_GPIO_WritePin(GPIOB, GPIO_PIN_10, GPIO_PIN_RESET);	//R_CCW
	HAL_GPIO_WritePin(GPIOC, GPIO_PIN_5, GPIO_PIN_SET);		//L_CW
	HAL_GPIO_WritePin(GPIOC, GPIO_PIN_4, GPIO_PIN_RESET);	//L_CCW

	pulse = pulse + 100;

	ConfigOC.Pulse = pulse;
	HAL_TIM_PWM_ConfigChannel(&htim2, &ConfigOC, TIM_CHANNEL_4);
	HAL_TIM_PWM_Start(&htim2, TIM_CHANNEL_4);

	ConfigOC.Pulse = pulse;
	HAL_TIM_PWM_ConfigChannel(&htim2, &ConfigOC, TIM_CHANNEL_1);
	HAL_TIM_PWM_Start(&htim2, TIM_CHANNEL_1);

	printf("PWM %4d \n", pulse);

	HAL_Delay(500);

	if(pulse >= 500)
	{
	pulse = 0;
	}
*/

/*Motor R&L rotate certain distance
	HAL_Delay(500);

	HAL_GPIO_WritePin(GPIOB, GPIO_PIN_0, GPIO_PIN_SET);		//STBY
	HAL_GPIO_WritePin(GPIOC, GPIO_PIN_5, GPIO_PIN_SET);		//L_CW
	HAL_GPIO_WritePin(GPIOC, GPIO_PIN_4, GPIO_PIN_RESET);	//L_CCW
	HAL_GPIO_WritePin(GPIOB, GPIO_PIN_1, GPIO_PIN_SET);		//R_CW
	HAL_GPIO_WritePin(GPIOB, GPIO_PIN_10, GPIO_PIN_RESET);	//R_CCW

	pulse = 50;

	ConfigOC.Pulse = pulse;
	HAL_TIM_PWM_ConfigChannel(&htim2, &ConfigOC, TIM_CHANNEL_1);
	HAL_TIM_PWM_Start(&htim2, TIM_CHANNEL_1);

	HAL_TIM_PWM_ConfigChannel(&htim2, &ConfigOC, TIM_CHANNEL_4);
	HAL_TIM_PWM_Start(&htim2, TIM_CHANNEL_4);

	while(dist_l < 150 && dist_r < 150);

	HAL_GPIO_WritePin(GPIOC, GPIO_PIN_5, GPIO_PIN_RESET);	//L_CW
	HAL_GPIO_WritePin(GPIOC, GPIO_PIN_4, GPIO_PIN_SET);		//L_CCW
	HAL_GPIO_WritePin(GPIOB, GPIO_PIN_1, GPIO_PIN_RESET);	//R_CW
	HAL_GPIO_WritePin(GPIOB, GPIO_PIN_10, GPIO_PIN_SET);	//R_CCW

	while(dist_l > 0 && dist_r > 0);

	HAL_GPIO_WritePin(GPIOC, GPIO_PIN_5, GPIO_PIN_SET);		//L_CW
	HAL_GPIO_WritePin(GPIOC, GPIO_PIN_4, GPIO_PIN_SET);		//L_CCW
	HAL_GPIO_WritePin(GPIOB, GPIO_PIN_1, GPIO_PIN_SET);		//R_CW
	HAL_GPIO_WritePin(GPIOB, GPIO_PIN_10, GPIO_PIN_SET);	//R_CCW

	while(1);
*/

/*speed control
	MF.FLAG.DRV = 1;
	for(int i = 0; i < 1; i++){
		HAL_Delay(500);
		target_speed_l = 600;
		target_speed_r = 600;
		while(dist_l < 1000 && dist_r < 1000);

		target_speed_l = -200;
		target_speed_r = -200;
		while(dist_l > 0 && dist_r > 0);

		target_speed_l = 0;
		target_speed_r = 0;
	}
	while(1);MF.FLAG.DRV = 0;
*/

/*accel & speed control & log get
	HAL_Delay(500);
	for(int i = 0; i < 1; i++){
		MF.FLAG.DRV = 1;
		MF.FLAG.LOG = 1;
		accel_l = 1000;
		accel_r = 1000;
		speed_max_l = 500;
		speed_max_r = 500;
		while(dist_l < 300 && dist_r < 300);

		accel_l = 1000;
		accel_r = 1000;
		speed_max_l = 0;
		speed_max_r = 0;
		speed_min_l = 0;
		speed_min_r = 0;
	}
	MF.FLAG.DRV = 0;

//log print
	while(HAL_GPIO_ReadPin(GPIOA, GPIO_PIN_11) == GPIO_PIN_SET);

	for(int i=0; i<log_allay; i++){
		printf("l:	%d\n", get_speed_l[i]);
		HAL_Delay(5);
	}
	for(int i=0; i<log_allay; i++){
		printf("r:	%d\n", get_speed_r[i]);
		HAL_Delay(5);
	}
*/

/*accel & speed control & log get +deaccel
	HAL_Delay(500);
	for(int i = 0; i < 1; i++){
		MF.FLAG.DRV = 1;
		MF.FLAG.LOG = 1;
		accel_l = 1000;
		accel_r = 1000;
		speed_max_l = 500;
		speed_max_r = 500;
		while(dist_l < 300 && dist_r < 300);

		accel_l = -1000;
		accel_r = -1000;
		speed_min_l = -500;
		speed_min_r = -500;
		while(dist_l > -300 && dist_r > -300);

		accel_l = 1000;
		accel_r = 1000;
		speed_max_l = 0;
		speed_max_r = 0;
		speed_min_l = 0;
		speed_min_r = 0;
	}
	MF.FLAG.DRV = 0;

//log print
	while(HAL_GPIO_ReadPin(GPIOA, GPIO_PIN_11) == GPIO_PIN_SET);

	for(int i=0; i<log_allay; i++){
		printf("l:	%d\n", get_speed_l[i]);
		HAL_Delay(5);
	}
	for(int i=0; i<log_allay; i++){
		printf("r:	%d\n", get_speed_r[i]);
		HAL_Delay(5);
	}
*/

/*turn Right
	MF.FLAG.DRV = 1;
	for(int i = 0; i < 4; i++){
		HAL_Delay(500);
	    if(i == 0) HAL_GPIO_WritePin(GPIOA, GPIO_PIN_4, GPIO_PIN_SET);
	    if(i == 1) HAL_GPIO_WritePin(GPIOA, GPIO_PIN_6, GPIO_PIN_SET);
	    if(i == 2) HAL_GPIO_WritePin(GPIOA, GPIO_PIN_7, GPIO_PIN_SET);

		target_speed_l = 200;
		target_speed_r = -200;
		while(dist_l < (TREAD*M_PI/4) && dist_r < (TREAD*M_PI/4));

		target_speed_l = 0;
		target_speed_r = 0;
	    HAL_GPIO_WritePin(GPIOA, GPIO_PIN_4, GPIO_PIN_RESET);
	    HAL_GPIO_WritePin(GPIOA, GPIO_PIN_6, GPIO_PIN_RESET);
	    HAL_GPIO_WritePin(GPIOA, GPIO_PIN_7, GPIO_PIN_RESET);
	    dist_l = 0;
	    dist_r = 0;
	}
	while(1)MF.FLAG.DRV = 0;
*/

/*turn Right (one wheel active)
	while(HAL_GPIO_ReadPin(GPIOA, GPIO_PIN_11) == GPIO_PIN_SET);
	MF.FLAG.DRV = 1;
	HAL_Delay(500);
	for(int i = 0; i < 1; i++){
		accel_l = 3000;
		accel_r = 0;
		speed_max_l = 200;
		speed_max_r = 0;
		while(dist_l < (TREAD*2*M_PI/4)*1.1);

		accel_l = -3000;
		speed_max_l = 0;
		//dist_l = 0;
		//dist_r = 0;
	}
	//while(1)MF.FLAG.DRV = 1;
	while(HAL_GPIO_ReadPin(GPIOA, GPIO_PIN_11) == GPIO_PIN_SET);
	dist_r2 = dist_r * 10;
	dist_l2 = dist_l * 10;
	printf("dist_l*10:	%d\n", dist_l2);
	printf("dist_r*10:	%d\n", dist_r2);
*/

/*turn Right (two wheel active)
	while(HAL_GPIO_ReadPin(GPIOA, GPIO_PIN_11) == GPIO_PIN_SET);
	MF.FLAG.DRV = 1;
	HAL_Delay(500);
	for(int i = 0; i < 1; i++){
		accel_l = 10000;
		accel_r = -10000;
		speed_max_l = 200;
		speed_min_r = -200;
		while(dist_l < (TREAD*M_PI/4));

		accel_l = -3000;
		accel_r = 3000;
		//dist_l = 0;
		//dist_r = 0;
	}
	//while(1)MF.FLAG.DRV = 1;
	while(HAL_GPIO_ReadPin(GPIOA, GPIO_PIN_11) == GPIO_PIN_SET);
	dist_r2 = dist_r * 10;
	dist_l2 = dist_l * 10;
	printf("dist_l*10:	%d\n", dist_l2);
	printf("dist_r*10:	%d\n", dist_r2);
*/

/*slalom R
	MF.FLAG.DRV = 1;
	for(int i = 0; i < 8; i++){
		HAL_Delay(500);

		target_speed_l = 200;
		target_speed_r = 200;
		while(dist_l < 10 && dist_r < 10);

		target_speed_l = 400;
		target_speed_r = 50;
	    dist_l = 0;
	    dist_r = 0;
		while((dist_l+dist_r)/2 < (TREAD*M_PI/2.5));

		target_speed_l = 200;
		target_speed_r = 200;
	    dist_l = 0;
	    dist_r = 0;
		while(dist_l < 10 && dist_r < 10);

		target_speed_l = 0;
		target_speed_r = 0;
	    dist_l = 0;
	    dist_r = 0;
	}
	while(1)MF.FLAG.DRV = 0;
*/

/*slalom R2
	MF.FLAG.DRV = 1;
	HAL_Delay(5000);
	for(int i = 0; i < 4; i++){

		accel_l = 3000;
		accel_r = 3000;
		speed_max_l = 400;
		speed_max_r = 400;
		dist_l = 0;
		dist_r = 0;
		while(dist_l < 110 && dist_r < 110);

		accel_l = 3000;
		accel_r = -3000;
		speed_max_l = 589;
		speed_min_r = 211;
		dist_l = 0;
		dist_r = 0;
		while((dist_l+dist_r)/2 < 110*1);//1.2

		accel_l = -3000;
		accel_r = 3000;
		speed_min_l = 400;
		speed_max_r = 400;
		dist_l = 0;
		dist_r = 0;
		while(dist_l < 110 && dist_r < 110);
	}
	while(1)MF.FLAG.DRV = 0;
*/

//voltage check
	if( HAL_GPIO_ReadPin(GPIOB, GPIO_PIN_12) == GPIO_PIN_RESET) {
	   HAL_GPIO_WritePin(GPIOC, GPIO_PIN_3, GPIO_PIN_SET);
	} else {
	   HAL_GPIO_WritePin(GPIOC, GPIO_PIN_3, GPIO_PIN_RESET);
	}

/*buzzer
	buzzer(DO, 500);
	buzzer(LE, 500);
	buzzer(MI, 500);
	buzzer(FA, 500);
	buzzer(SO, 500);
	buzzer(LA, 500);
	buzzer(SI, 500);
	buzzer(DOO, 500);
*/

/*buzzer pitagola
	while(HAL_GPIO_ReadPin(GPIOA, GPIO_PIN_11) == GPIO_PIN_SET);

	buzzer(LE, 200);
	buzzer(MI, 200);
	buzzer(RST, 50);
	buzzer(LE, 200);
	buzzer(MI, 200);
	buzzer(RST, 50);
	buzzer(DOO, 200);
	buzzer(SI, 200);
	buzzer(RST, 120);
	buzzer(SO, 250);
	buzzer(RST, 1000);
*/

/*buzzer pitagola 2
	while(HAL_GPIO_ReadPin(GPIOA, GPIO_PIN_11) == GPIO_PIN_SET);

	for(int i=0; i<pita; i++){
		buzzer(pitagola[i][0], pitagola[i][1]);
	}
*/

/*gyro who am i check
	uint8_t who_am_i;

	HAL_Delay(100); // wait start up
	who_am_i = read_byte(WHO_AM_I); // 1. read who am i
	printf("WHO_AM_I:	0x%x\n",who_am_i); // 2. check who am i value
	// 2. error check
	if ( who_am_i != 0x98 ){
		while(1){
			printf( "gyro_error\r");
		}
	}
	HAL_Delay(50); // wait
	write_byte(PWR_MGMT_1, 0x00); // 3. set pwr_might

	HAL_Delay(50);
	write_byte(CONFIG, 0x00); // 4. set config

	HAL_Delay(50);
	write_byte(GYRO_CONFIG, 0x18); // 5. set gyro config

	HAL_Delay(50);
	while(HAL_GPIO_ReadPin(GPIOA, GPIO_PIN_11) == GPIO_PIN_SET);
*/

/*gyro z read
	int gyro_z2, degree_z2;
	gyro_z2 = gyro_read_z() * 10;
	degree_z2 = degree_z * 10;
	printf("gyro_z*10: %3d, degree*10: %3d\n", gyro_z2, degree_z2);
	HAL_Delay(5);
*/

/*enkaigei
	while(HAL_GPIO_ReadPin(GPIOA, GPIO_PIN_11) == GPIO_PIN_SET);
	target_degree_z = degree_z;
	accel_l = 3000;

	MF.FLAG.ENKAI = 1;

	while(1);
*/

/*new turn Right
	while(HAL_GPIO_ReadPin(GPIOA, GPIO_PIN_11) == GPIO_PIN_SET);
	MF.FLAG.DRV = 1;
	HAL_Delay(500);
	for(int i = 0; i < 16; i++){
		target_omega_z = 800;
		accel_l = 3000;
		accel_r = -3000;
		speed_max_l = target_omega_z/180*M_PI * TREAD/2;
		speed_min_r = -1*target_omega_z/180*M_PI * TREAD/2;
		degree_z = 0;
		while(degree_z > -80);
		accel_l = 3000;
		accel_r = -3000;
		speed_max_l = 100;
		speed_min_r = -100;
		degree_z = 0;
		while(degree_z > -90+80);

	}
	while(1)MF.FLAG.DRV = 0;;
*/

/*new slalom R
	while(HAL_GPIO_ReadPin(GPIOA, GPIO_PIN_11) == GPIO_PIN_SET);
	MF.FLAG.DRV = 1;
	HAL_Delay(500);
	for(int i = 0; i < 4; i++){

		accel_l = 3000;
		accel_r = 3000;
		speed_max_l = 400;
		speed_max_r = 400;
		dist_l = 0;
		dist_r = 0;
		while(dist_l < 40 && dist_r < 40);

		accel_l = 10000;
		accel_r = -10000;
		speed_max_l = 589;
		speed_min_r = 211;
		dist_l = 0;
		dist_r = 0;
		degree_z = 0;
		while(degree_z > -90);//1.2

		accel_l = -10000;
		accel_r = 10000;
		speed_min_l = 400;
		speed_max_r = 400;
		dist_l = 0;
		dist_r = 0;
		while(dist_l < 40 && dist_r < 40);
	}
	while(1)MF.FLAG.DRV = 0;
*/

/*new slalom L
	while(HAL_GPIO_ReadPin(GPIOA, GPIO_PIN_11) == GPIO_PIN_SET);
	MF.FLAG.DRV = 1;
	HAL_Delay(500);
	for(int i = 0; i < 1; i++){

		accel_l = 3000;
		accel_r = 3000;
		speed_max_l = 400;
		speed_max_r = 400;
		dist_l = 0;
		dist_r = 0;
		while(dist_l < 40 && dist_r < 40);

		accel_l = -10000;
		accel_r = 10000;
		speed_min_l = 211;
		speed_max_r = 589;
		dist_l = 0;
		dist_r = 0;
		degree_z = 0;
		while(degree_z < 90);

		accel_l = 10000;
		accel_r = -10000;
		speed_max_l = 400;
		speed_min_r = 400;
		dist_l = 0;
		dist_r = 0;
		while(dist_l < 40 && dist_r < 40);
	}
	while(1)MF.FLAG.DRV = 0;
*/

/*new new slalom R
	while(HAL_GPIO_ReadPin(GPIOA, GPIO_PIN_11) == GPIO_PIN_SET);
	HAL_Delay(500);
	for(int i = 0; i < 8; i++){
		MF.FLAG.DRV = 1;
		MF.FLAG.GYR = 0;

		accel_l = 3000;
		accel_r = 3000;
		speed_max_l = 400;
		speed_max_r = 400;
		dist_l = 0;
		dist_r = 0;
		while(dist_l < 18.5 && dist_r < 18.5);
		MF.FLAG.DRV = 0;
		MF.FLAG.GYR = 1;

		target_degaccel_z = 4000;
		omega_max = 550;
		speed_G = 400;
		degree_z = 0;
		while(degree_z > -38.087);
		MF.FLAG.DRV = 0;
		MF.FLAG.GYR = 1;

		target_degaccel_z = 0;
		omega_max = 550;
		degree_z = 0;
		while(degree_z > -19);
		MF.FLAG.DRV = 0;
		MF.FLAG.GYR = 1;

		target_degaccel_z = -4000;
		omega_max = 550;
		degree_z = 0;
		while(degree_z > -31.913);
		MF.FLAG.DRV = 1;
		MF.FLAG.GYR = 0;

		accel_l = 3000;
		accel_r = 3000;
		speed_max_l = 400;
		speed_max_r = 400;
		dist_l = 0;
		dist_r = 0;
		while(dist_l < 18.5 && dist_r < 18.5);
	}
	while(1)MF.FLAG.DRV = 0;
*/

    /* USER CODE END WHILE */

  }
}

void SystemClock_Config(void)
{
  RCC_OscInitTypeDef RCC_OscInitStruct = {0};
  RCC_ClkInitTypeDef RCC_ClkInitStruct = {0};

  /** Configure the main internal regulator output voltage
  */
  __HAL_RCC_PWR_CLK_ENABLE();
  __HAL_PWR_VOLTAGESCALING_CONFIG(PWR_REGULATOR_VOLTAGE_SCALE1);
  /** Initializes the CPU, AHB and APB busses clocks
  */
  RCC_OscInitStruct.OscillatorType = RCC_OSCILLATORTYPE_HSI;
  RCC_OscInitStruct.HSIState = RCC_HSI_ON;
  RCC_OscInitStruct.HSICalibrationValue = RCC_HSICALIBRATION_DEFAULT;
  RCC_OscInitStruct.PLL.PLLState = RCC_PLL_ON;
  RCC_OscInitStruct.PLL.PLLSource = RCC_PLLSOURCE_HSI;
  RCC_OscInitStruct.PLL.PLLM = 8;
  RCC_OscInitStruct.PLL.PLLN = 168;
  RCC_OscInitStruct.PLL.PLLP = RCC_PLLP_DIV2;
  RCC_OscInitStruct.PLL.PLLQ = 4;
  if (HAL_RCC_OscConfig(&RCC_OscInitStruct) != HAL_OK)
  {
    Error_Handler();
  }
  /** Initializes the CPU, AHB and APB busses clocks
  */
  RCC_ClkInitStruct.ClockType = RCC_CLOCKTYPE_HCLK|RCC_CLOCKTYPE_SYSCLK
                              |RCC_CLOCKTYPE_PCLK1|RCC_CLOCKTYPE_PCLK2;
  RCC_ClkInitStruct.SYSCLKSource = RCC_SYSCLKSOURCE_PLLCLK;
  RCC_ClkInitStruct.AHBCLKDivider = RCC_SYSCLK_DIV1;
  RCC_ClkInitStruct.APB1CLKDivider = RCC_HCLK_DIV4;
  RCC_ClkInitStruct.APB2CLKDivider = RCC_HCLK_DIV2;

  if (HAL_RCC_ClockConfig(&RCC_ClkInitStruct, FLASH_LATENCY_5) != HAL_OK)
  {
    Error_Handler();
  }
}

static void MX_ADC1_Init(void)
{

  ADC_ChannelConfTypeDef sConfig = {0};

  /** Configure the global features of the ADC (Clock, Resolution, Data Alignment and number of conversion)
  */
  hadc1.Instance = ADC1;
  hadc1.Init.ClockPrescaler = ADC_CLOCK_SYNC_PCLK_DIV4;
  hadc1.Init.Resolution = ADC_RESOLUTION_12B;
  hadc1.Init.ScanConvMode = DISABLE;
  hadc1.Init.ContinuousConvMode = DISABLE;
  hadc1.Init.DiscontinuousConvMode = DISABLE;
  hadc1.Init.ExternalTrigConvEdge = ADC_EXTERNALTRIGCONVEDGE_NONE;
  hadc1.Init.ExternalTrigConv = ADC_SOFTWARE_START;
  hadc1.Init.DataAlign = ADC_DATAALIGN_RIGHT;
  hadc1.Init.NbrOfConversion = 1;
  hadc1.Init.DMAContinuousRequests = DISABLE;
  hadc1.Init.EOCSelection = ADC_EOC_SINGLE_CONV;
  if (HAL_ADC_Init(&hadc1) != HAL_OK)
  {
    Error_Handler();
  }
  /** Configure for the selected ADC regular channel its corresponding rank in the sequencer and its sample time.
  */
  sConfig.Channel = ADC_CHANNEL_0;
  sConfig.Rank = 1;
  sConfig.SamplingTime = ADC_SAMPLETIME_3CYCLES;
  if (HAL_ADC_ConfigChannel(&hadc1, &sConfig) != HAL_OK)
  {
    Error_Handler();
  }

}

static void MX_SPI3_Init(void)
{

  /* SPI3 parameter configuration*/
  hspi3.Instance = SPI3;
  hspi3.Init.Mode = SPI_MODE_MASTER;
  hspi3.Init.Direction = SPI_DIRECTION_2LINES;
  hspi3.Init.DataSize = SPI_DATASIZE_8BIT;
  hspi3.Init.CLKPolarity = SPI_POLARITY_LOW;
  hspi3.Init.CLKPhase = SPI_PHASE_1EDGE;
  hspi3.Init.NSS = SPI_NSS_SOFT;
  hspi3.Init.BaudRatePrescaler = SPI_BAUDRATEPRESCALER_16;
  hspi3.Init.FirstBit = SPI_FIRSTBIT_MSB;
  hspi3.Init.TIMode = SPI_TIMODE_DISABLE;
  hspi3.Init.CRCCalculation = SPI_CRCCALCULATION_DISABLE;
  hspi3.Init.CRCPolynomial = 10;
  if (HAL_SPI_Init(&hspi3) != HAL_OK)
  {
    Error_Handler();
  }

}

static void MX_TIM2_Init(void)
{

  TIM_ClockConfigTypeDef sClockSourceConfig = {0};
  TIM_MasterConfigTypeDef sMasterConfig = {0};
  TIM_OC_InitTypeDef sConfigOC = {0};

  htim2.Instance = TIM2;
  htim2.Init.Prescaler = 0;
  htim2.Init.CounterMode = TIM_COUNTERMODE_UP;
  htim2.Init.Period = 1000-1;
  htim2.Init.ClockDivision = TIM_CLOCKDIVISION_DIV1;
  htim2.Init.AutoReloadPreload = TIM_AUTORELOAD_PRELOAD_DISABLE;
  if (HAL_TIM_Base_Init(&htim2) != HAL_OK)
  {
    Error_Handler();
  }
  sClockSourceConfig.ClockSource = TIM_CLOCKSOURCE_INTERNAL;
  if (HAL_TIM_ConfigClockSource(&htim2, &sClockSourceConfig) != HAL_OK)
  {
    Error_Handler();
  }
  if (HAL_TIM_PWM_Init(&htim2) != HAL_OK)
  {
    Error_Handler();
  }
  sMasterConfig.MasterOutputTrigger = TIM_TRGO_RESET;
  sMasterConfig.MasterSlaveMode = TIM_MASTERSLAVEMODE_DISABLE;
  if (HAL_TIMEx_MasterConfigSynchronization(&htim2, &sMasterConfig) != HAL_OK)
  {
    Error_Handler();
  }
  sConfigOC.OCMode = TIM_OCMODE_PWM1;
  sConfigOC.Pulse = 0;
  sConfigOC.OCPolarity = TIM_OCPOLARITY_HIGH;
  sConfigOC.OCFastMode = TIM_OCFAST_DISABLE;
  if (HAL_TIM_PWM_ConfigChannel(&htim2, &sConfigOC, TIM_CHANNEL_1) != HAL_OK)
  {
    Error_Handler();
  }
  if (HAL_TIM_PWM_ConfigChannel(&htim2, &sConfigOC, TIM_CHANNEL_4) != HAL_OK)
  {
    Error_Handler();
  }
  HAL_TIM_MspPostInit(&htim2);

}

static void MX_TIM3_Init(void)
{

  TIM_ClockConfigTypeDef sClockSourceConfig = {0};
  TIM_MasterConfigTypeDef sMasterConfig = {0};
  TIM_OC_InitTypeDef sConfigOC = {0};

  htim3.Instance = TIM3;
  htim3.Init.Prescaler = 84-1;
  htim3.Init.CounterMode = TIM_COUNTERMODE_UP;
  htim3.Init.Period = 0;
  htim3.Init.ClockDivision = TIM_CLOCKDIVISION_DIV1;
  htim3.Init.AutoReloadPreload = TIM_AUTORELOAD_PRELOAD_DISABLE;
  if (HAL_TIM_Base_Init(&htim3) != HAL_OK)
  {
    Error_Handler();
  }
  sClockSourceConfig.ClockSource = TIM_CLOCKSOURCE_INTERNAL;
  if (HAL_TIM_ConfigClockSource(&htim3, &sClockSourceConfig) != HAL_OK)
  {
    Error_Handler();
  }
  if (HAL_TIM_PWM_Init(&htim3) != HAL_OK)
  {
    Error_Handler();
  }
  sMasterConfig.MasterOutputTrigger = TIM_TRGO_RESET;
  sMasterConfig.MasterSlaveMode = TIM_MASTERSLAVEMODE_DISABLE;
  if (HAL_TIMEx_MasterConfigSynchronization(&htim3, &sMasterConfig) != HAL_OK)
  {
    Error_Handler();
  }
  sConfigOC.OCMode = TIM_OCMODE_PWM1;
  sConfigOC.Pulse = 0;
  sConfigOC.OCPolarity = TIM_OCPOLARITY_HIGH;
  sConfigOC.OCFastMode = TIM_OCFAST_DISABLE;
  if (HAL_TIM_PWM_ConfigChannel(&htim3, &sConfigOC, TIM_CHANNEL_2) != HAL_OK)
  {
    Error_Handler();
  }
  HAL_TIM_MspPostInit(&htim3);

}

static void MX_TIM4_Init(void)
{

  TIM_Encoder_InitTypeDef sConfig = {0};
  TIM_MasterConfigTypeDef sMasterConfig = {0};

  htim4.Instance = TIM4;
  htim4.Init.Prescaler = 0;
  htim4.Init.CounterMode = TIM_COUNTERMODE_UP;
  htim4.Init.Period = 65535;
  htim4.Init.ClockDivision = TIM_CLOCKDIVISION_DIV1;
  htim4.Init.AutoReloadPreload = TIM_AUTORELOAD_PRELOAD_DISABLE;
  sConfig.EncoderMode = TIM_ENCODERMODE_TI12;
  sConfig.IC1Polarity = TIM_ICPOLARITY_RISING;
  sConfig.IC1Selection = TIM_ICSELECTION_DIRECTTI;
  sConfig.IC1Prescaler = TIM_ICPSC_DIV1;
  sConfig.IC1Filter = 0;
  sConfig.IC2Polarity = TIM_ICPOLARITY_RISING;
  sConfig.IC2Selection = TIM_ICSELECTION_DIRECTTI;
  sConfig.IC2Prescaler = TIM_ICPSC_DIV1;
  sConfig.IC2Filter = 0;
  if (HAL_TIM_Encoder_Init(&htim4, &sConfig) != HAL_OK)
  {
    Error_Handler();
  }
  sMasterConfig.MasterOutputTrigger = TIM_TRGO_RESET;
  sMasterConfig.MasterSlaveMode = TIM_MASTERSLAVEMODE_DISABLE;
  if (HAL_TIMEx_MasterConfigSynchronization(&htim4, &sMasterConfig) != HAL_OK)
  {
    Error_Handler();
  }

}

static void MX_TIM6_Init(void)
{

  TIM_MasterConfigTypeDef sMasterConfig = {0};

  htim6.Instance = TIM6;
  htim6.Init.Prescaler = 84-1;
  htim6.Init.CounterMode = TIM_COUNTERMODE_UP;
  htim6.Init.Period = 1000-1;
  htim6.Init.AutoReloadPreload = TIM_AUTORELOAD_PRELOAD_DISABLE;
  if (HAL_TIM_Base_Init(&htim6) != HAL_OK)
  {
    Error_Handler();
  }
  sMasterConfig.MasterOutputTrigger = TIM_TRGO_RESET;
  sMasterConfig.MasterSlaveMode = TIM_MASTERSLAVEMODE_DISABLE;
  if (HAL_TIMEx_MasterConfigSynchronization(&htim6, &sMasterConfig) != HAL_OK)
  {
    Error_Handler();
  }

}

static void MX_TIM8_Init(void)
{

  TIM_Encoder_InitTypeDef sConfig = {0};
  TIM_MasterConfigTypeDef sMasterConfig = {0};

  htim8.Instance = TIM8;
  htim8.Init.Prescaler = 0;
  htim8.Init.CounterMode = TIM_COUNTERMODE_UP;
  htim8.Init.Period = 65535;
  htim8.Init.ClockDivision = TIM_CLOCKDIVISION_DIV1;
  htim8.Init.RepetitionCounter = 0;
  htim8.Init.AutoReloadPreload = TIM_AUTORELOAD_PRELOAD_DISABLE;
  sConfig.EncoderMode = TIM_ENCODERMODE_TI12;
  sConfig.IC1Polarity = TIM_ICPOLARITY_RISING;
  sConfig.IC1Selection = TIM_ICSELECTION_DIRECTTI;
  sConfig.IC1Prescaler = TIM_ICPSC_DIV1;
  sConfig.IC1Filter = 0;
  sConfig.IC2Polarity = TIM_ICPOLARITY_RISING;
  sConfig.IC2Selection = TIM_ICSELECTION_DIRECTTI;
  sConfig.IC2Prescaler = TIM_ICPSC_DIV1;
  sConfig.IC2Filter = 0;
  if (HAL_TIM_Encoder_Init(&htim8, &sConfig) != HAL_OK)
  {
    Error_Handler();
  }
  sMasterConfig.MasterOutputTrigger = TIM_TRGO_RESET;
  sMasterConfig.MasterSlaveMode = TIM_MASTERSLAVEMODE_DISABLE;
  if (HAL_TIMEx_MasterConfigSynchronization(&htim8, &sMasterConfig) != HAL_OK)
  {
    Error_Handler();
  }

}

static void MX_USART1_UART_Init(void)
{

  huart1.Instance = USART1;
  huart1.Init.BaudRate = 9600;
  huart1.Init.WordLength = UART_WORDLENGTH_8B;
  huart1.Init.StopBits = UART_STOPBITS_1;
  huart1.Init.Parity = UART_PARITY_NONE;
  huart1.Init.Mode = UART_MODE_TX_RX;
  huart1.Init.HwFlowCtl = UART_HWCONTROL_NONE;
  huart1.Init.OverSampling = UART_OVERSAMPLING_16;
  if (HAL_UART_Init(&huart1) != HAL_OK)
  {
    Error_Handler();
  }

}

static void MX_GPIO_Init(void)
{
  GPIO_InitTypeDef GPIO_InitStruct = {0};

  /* GPIO Ports Clock Enable */
  __HAL_RCC_GPIOC_CLK_ENABLE();
  __HAL_RCC_GPIOA_CLK_ENABLE();
  __HAL_RCC_GPIOB_CLK_ENABLE();
  __HAL_RCC_GPIOD_CLK_ENABLE();

  /*Configure GPIO pin Output Level */
  HAL_GPIO_WritePin(GPIOC, GPIO_PIN_13|GPIO_PIN_14|GPIO_PIN_15|GPIO_PIN_2
                          |GPIO_PIN_3|GPIO_PIN_4|GPIO_PIN_5|GPIO_PIN_9, GPIO_PIN_RESET);

  /*Configure GPIO pin Output Level */
  HAL_GPIO_WritePin(GPIOA, GPIO_PIN_4|GPIO_PIN_6|GPIO_PIN_7|GPIO_PIN_8, GPIO_PIN_RESET);

  /*Configure GPIO pin Output Level */
  HAL_GPIO_WritePin(GPIOB, GPIO_PIN_0|GPIO_PIN_1|GPIO_PIN_10|GPIO_PIN_13
                          |GPIO_PIN_8|GPIO_PIN_9, GPIO_PIN_RESET);

  /*Configure GPIO pin Output Level */
  HAL_GPIO_WritePin(GPIOD, GPIO_PIN_2, GPIO_PIN_RESET);

  /*Configure GPIO pins : PC13 PC14 PC15 PC2
                           PC3 PC4 PC5 PC9 */
  GPIO_InitStruct.Pin = GPIO_PIN_13|GPIO_PIN_14|GPIO_PIN_15|GPIO_PIN_2
                          |GPIO_PIN_3|GPIO_PIN_4|GPIO_PIN_5|GPIO_PIN_9;
  GPIO_InitStruct.Mode = GPIO_MODE_OUTPUT_PP;
  GPIO_InitStruct.Pull = GPIO_NOPULL;
  GPIO_InitStruct.Speed = GPIO_SPEED_FREQ_LOW;
  HAL_GPIO_Init(GPIOC, &GPIO_InitStruct);

  /*Configure GPIO pins : PA4 PA6 PA7 PA8 */
  GPIO_InitStruct.Pin = GPIO_PIN_4|GPIO_PIN_6|GPIO_PIN_7|GPIO_PIN_8;
  GPIO_InitStruct.Mode = GPIO_MODE_OUTPUT_PP;
  GPIO_InitStruct.Pull = GPIO_NOPULL;
  GPIO_InitStruct.Speed = GPIO_SPEED_FREQ_LOW;
  HAL_GPIO_Init(GPIOA, &GPIO_InitStruct);

  /*Configure GPIO pins : PB0 PB1 PB10 PB13
                           PB8 PB9 */
  GPIO_InitStruct.Pin = GPIO_PIN_0|GPIO_PIN_1|GPIO_PIN_10|GPIO_PIN_13
                          |GPIO_PIN_8|GPIO_PIN_9;
  GPIO_InitStruct.Mode = GPIO_MODE_OUTPUT_PP;
  GPIO_InitStruct.Pull = GPIO_NOPULL;
  GPIO_InitStruct.Speed = GPIO_SPEED_FREQ_LOW;
  HAL_GPIO_Init(GPIOB, &GPIO_InitStruct);

  /*Configure GPIO pin : PB12 */
  GPIO_InitStruct.Pin = GPIO_PIN_12;
  GPIO_InitStruct.Mode = GPIO_MODE_INPUT;
  GPIO_InitStruct.Pull = GPIO_PULLUP;
  HAL_GPIO_Init(GPIOB, &GPIO_InitStruct);

  /*Configure GPIO pin : PA11 */
  GPIO_InitStruct.Pin = GPIO_PIN_11;
  GPIO_InitStruct.Mode = GPIO_MODE_INPUT;
  GPIO_InitStruct.Pull = GPIO_NOPULL;
  HAL_GPIO_Init(GPIOA, &GPIO_InitStruct);

  /*Configure GPIO pin : PD2 */
  GPIO_InitStruct.Pin = GPIO_PIN_2;
  GPIO_InitStruct.Mode = GPIO_MODE_OUTPUT_PP;
  GPIO_InitStruct.Pull = GPIO_NOPULL;
  GPIO_InitStruct.Speed = GPIO_SPEED_FREQ_LOW;
  HAL_GPIO_Init(GPIOD, &GPIO_InitStruct);

}

/* USER CODE BEGIN 4 */

void buzzer(int sound, int length){

	TIM_OC_InitTypeDef ConfigOC;
	ConfigOC.OCMode = TIM_OCMODE_PWM1;
	ConfigOC.OCPolarity = TIM_OCPOLARITY_HIGH;
	ConfigOC.OCFastMode = TIM_OCFAST_DISABLE;

	hz = 1000000 / sound;
	TIM3 -> ARR = hz;

    ConfigOC.Pulse = hz / 2;
    HAL_TIM_PWM_ConfigChannel(&htim3, &ConfigOC, TIM_CHANNEL_2);
    HAL_TIM_PWM_Start(&htim3, TIM_CHANNEL_2);

	HAL_Delay(length);

}

//+++++++++++++++++++++++++++++++++++++++++++++++
//get_adc_value
// ???��?��??��?��?定されたチャンネルのアナログ電圧値を取り�????��?��??��?��???��?��??��?��?
// 引数1????��?��??��?��???��?��??��?��hadc …… 電圧値を取り�????��?��??��?��すチャンネルが属すADCのHandler
// 引数2????��?��??��?��???��?��??��?��channel …… 電圧値を取り�????��?��??��?��すチャンネル
// 戻り�????��?��??��?��????��?��??��?��???��?��??��?��電圧値????��?��??��?��?12bit???��?��??��?��?解能????��?��??��?��?
//+++++++++++++++++++++++++++++++++++++++++++++++
int get_adc_value(ADC_HandleTypeDef *hadc, uint32_t channel){

  ADC_ChannelConfTypeDef sConfig = {0};

  sConfig.Channel = channel;
  sConfig.Rank = 1;
  //sConfig.SingleDiff = ADC_SINGLE_ENDED;
  sConfig.SamplingTime = ADC_SAMPLETIME_3CYCLES;
  //sConfig.OffsetNumber = ADC_OFFSET_NONE;
  sConfig.Offset = 0;

  HAL_ADC_ConfigChannel(hadc, &sConfig);

  HAL_ADC_Start(hadc);                    // AD変換を開始す???��?��??��?��?
  HAL_ADC_PollForConversion(hadc, 100);   // AD変換終�?まで???��?��??��?��?機す???��?��??��?��?
  return HAL_ADC_GetValue(hadc);          // AD変換結果を取得す???��?��??��?��?
}

/*HAL_ADC_ConvHalfCpltCallback(ADC_HandleTypeDef* hadc)
{
	printf("ADC CH0 Value is %d\r\n",aADCxConvertedData[0]);
	printf("ADC CH1 Value is %d\r\n",aADCxConvertedData[1]);
	printf("ADC CH2 Value is %d\r\n",aADCxConvertedData[2]);
	printf("ADC CH3 Value is %d\r\n",aADCxConvertedData[3]);
}
*/

void gyro_init(void){
  uint8_t who_am_i;

  HAL_Delay(100); // wait start up
  who_am_i = read_byte(WHO_AM_I); // 1. read who am i
  printf("0x%x\r\n",who_am_i); // 2. check who am i value

  // 2. error check
  if (who_am_i != 0x98){
    while(1){
      printf( "gyro_error\r");
    }
  }

  HAL_Delay(50); // wait
  write_byte(PWR_MGMT_1, 0x00); // 3. set pwr_might

  HAL_Delay(50);
  write_byte(CONFIG, 0x00); // 4. set config

  HAL_Delay(50);
  write_byte(GYRO_CONFIG, 0x18); // 5. set gyro config

  HAL_Delay(50);
}

uint8_t read_byte(uint8_t reg){
  uint8_t ret,val;
  HAL_GPIO_WritePin(GPIOD, GPIO_PIN_2, GPIO_PIN_RESET ); //cs = Low;
  ret = reg | 0x80;  // MSB = 1
  HAL_SPI_Transmit(&hspi3, &ret,1,100); // sent 1byte(address)
  HAL_SPI_Receive(&hspi3,&val,1,100); // read 1byte(read data)
  HAL_GPIO_WritePin(GPIOD, GPIO_PIN_2, GPIO_PIN_SET );  //cs = High;
  return val;
}

void write_byte(uint8_t reg, uint8_t val){
  uint8_t ret;
  ret = reg & 0x7F ; // MSB = 0
  HAL_GPIO_WritePin(GPIOD, GPIO_PIN_2, GPIO_PIN_RESET); // cs = Low;
  HAL_SPI_Transmit(&hspi3, &ret,1,100); // sent 1byte(address)
  HAL_SPI_Transmit(&hspi3, &val,1,100); // read 1byte(write data)
  HAL_GPIO_WritePin(GPIOD, GPIO_PIN_2, GPIO_PIN_SET); // cs = High;
}

float gyro_read_z(void){
  int16_t gyro_z;
  float omega;

  // H:8bit shift, Link h and l
  gyro_z = (int16_t)((int16_t)(read_byte(GYRO_ZOUT_H) << 8) | read_byte(GYRO_ZOUT_L));

  omega = (float)(gyro_z / GYRO_FACTOR+1.15); // dps to deg/sec
  return omega;
}

//+++++++++++++++++++++++++++++++++++++++++++++++
//drive_dir
// wheel turn dir for each wheel
// hikisuu:1-wheel select(0=>L, 1=>R), 2-dir select(0=>CW, 1=>CWW, 2=>ShortBrake, 3=>free)
// modorichi: nothing
//+++++++++++++++++++++++++++++++++++++++++++++++
void drive_dir(uint8_t wheel, uint8_t dir){
	if(wheel == 0){
		if(dir == 0){
			HAL_GPIO_WritePin(GPIOC, GPIO_PIN_5, GPIO_PIN_SET);		//L_CW
			HAL_GPIO_WritePin(GPIOC, GPIO_PIN_4, GPIO_PIN_RESET);	//L_CCW
			HAL_GPIO_WritePin(GPIOB, GPIO_PIN_0, GPIO_PIN_SET);		//STBY
		}else if(dir == 1){
			HAL_GPIO_WritePin(GPIOC, GPIO_PIN_5, GPIO_PIN_RESET);	//L_CW
			HAL_GPIO_WritePin(GPIOC, GPIO_PIN_4, GPIO_PIN_SET);		//L_CCW
			HAL_GPIO_WritePin(GPIOB, GPIO_PIN_0, GPIO_PIN_SET);		//STBY
		}else if(dir == 2){
			HAL_GPIO_WritePin(GPIOC, GPIO_PIN_5, GPIO_PIN_SET);		//L_CW
			HAL_GPIO_WritePin(GPIOC, GPIO_PIN_4, GPIO_PIN_SET);		//L_CCW
			HAL_GPIO_WritePin(GPIOB, GPIO_PIN_0, GPIO_PIN_SET);		//STBY
		}else{
			HAL_GPIO_WritePin(GPIOB, GPIO_PIN_0, GPIO_PIN_RESET);	//STBY
		}
	}else{
		if(dir == 0){
			HAL_GPIO_WritePin(GPIOB, GPIO_PIN_1, GPIO_PIN_SET);		//R_CW
			HAL_GPIO_WritePin(GPIOB, GPIO_PIN_10, GPIO_PIN_RESET);	//R_CCW
			HAL_GPIO_WritePin(GPIOB, GPIO_PIN_0, GPIO_PIN_SET);		//STBY
		}else if(dir == 1){
			HAL_GPIO_WritePin(GPIOB, GPIO_PIN_1, GPIO_PIN_RESET);	//R_CW
			HAL_GPIO_WritePin(GPIOB, GPIO_PIN_10, GPIO_PIN_SET);	//R_CCW
			HAL_GPIO_WritePin(GPIOB, GPIO_PIN_0, GPIO_PIN_SET);		//STBY
		}else if(dir == 2){
			HAL_GPIO_WritePin(GPIOB, GPIO_PIN_1, GPIO_PIN_SET);		//R_CW
			HAL_GPIO_WritePin(GPIOB, GPIO_PIN_10, GPIO_PIN_SET);	//R_CCW
			HAL_GPIO_WritePin(GPIOB, GPIO_PIN_0, GPIO_PIN_SET);		//STBY
		}else{
			HAL_GPIO_WritePin(GPIOB, GPIO_PIN_0, GPIO_PIN_RESET);	//STBY
		}
	}
}

/* USER CODE END 4 */

void Error_Handler(void)
{
}

/************************ (C) COPYRIGHT STMicroelectronics *****END OF FILE****/
